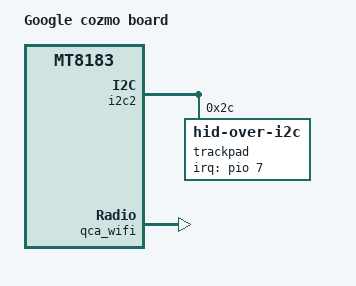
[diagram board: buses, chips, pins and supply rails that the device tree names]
// SPDX-License-Identifier: (GPL-2.0 OR MIT)
/*
 * Copyright 2021 Google LLC
 */

/dts-v1/;
#include "mt8183-kukui-jacuzzi.dtsi"
#include "mt8183-kukui-audio-ts3a227e-max98357a.dtsi"

/ {
	model = "Google cozmo board";
	chassis-type = "laptop";
	compatible = "google,cozmo", "mediatek,mt8183";
};

&i2c_tunnel {
	google,remote-bus = <0>;
};

&i2c2 {
	i2c-scl-internal-delay-ns = <25000>;

	trackpad@2c {
		compatible = "hid-over-i2c";
		reg = <0x2c>;
		hid-descr-addr = <0x20>;

		pinctrl-names = "default";
		pinctrl-0 = <&trackpad_pins>;

		interrupts-extended = <&pio 7 IRQ_TYPE_LEVEL_LOW>;

		wakeup-source;
	};
};

&qca_wifi {
	qcom,ath10k-calibration-variant = "GO_COZMO";
};
